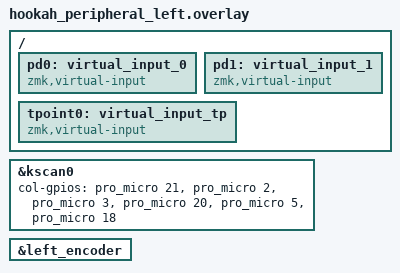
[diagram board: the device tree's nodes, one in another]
#include "hookah.dtsi"

&kscan0 {
    col-gpios
        = <&pro_micro 21 GPIO_ACTIVE_HIGH>
        , <&pro_micro 2 GPIO_ACTIVE_HIGH>
        , <&pro_micro 3 GPIO_ACTIVE_HIGH>
        , <&pro_micro 20 GPIO_ACTIVE_HIGH>
        , <&pro_micro 5 GPIO_ACTIVE_HIGH>
        , <&pro_micro 18 GPIO_ACTIVE_HIGH>
        ;
};

&left_encoder {
    status = "okay";
};



/{
    pd0: virtual_input_0 {
		compatible = "zmk,virtual-input";
	};
	pd1: virtual_input_1 {
		compatible = "zmk,virtual-input";
	};
    tpoint0: virtual_input_tp {
		compatible = "zmk,virtual-input";
	};
    // There's no relay here, so nothing will be communicating.
};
